# STMP3770 register map
Vendor: Freescale Semiconductor (NXP); Series: STMP37xx; File version: 1.0
CPU: other r0p0, little endian, no MPU, no FPU, 2 interrupt priority bits
Registers are 32-bit, read-write, reset 0x0 unless marked. A register's access mark holds for its fields unless they carry their own. Offsets are from the block's base; [hi:lo] are bit positions; {n}, {i} and the like mark numbered series.

## DRAM — DRAM 控制器(mDDR/SDRAM 时序、刷新与校准配置寄存器)
Base 0x800E0000
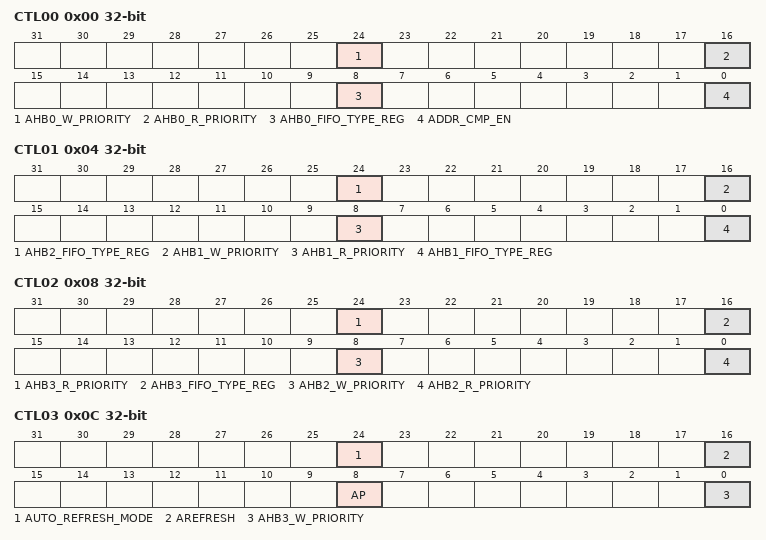
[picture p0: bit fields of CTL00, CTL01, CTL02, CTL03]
0x00 CTL00 — DRAM Control Register 00
  [24] AHB0_W_PRIORITY — Ahb0 W Priority，1位读写字段。
  [16] AHB0_R_PRIORITY — Ahb0 R Priority，1位读写字段。
  [8] AHB0_FIFO_TYPE_REG — Ahb0 Fifo Type Reg，1位读写字段。
  [0] ADDR_CMP_EN — Addr Cmp En，1位读写字段。
0x04 CTL01 — DRAM Control Register 01
  [24] AHB2_FIFO_TYPE_REG — Ahb2 Fifo Type Reg，1位读写字段。
  [16] AHB1_W_PRIORITY — Ahb1 W Priority，1位读写字段。
  [8] AHB1_R_PRIORITY — Ahb1 R Priority，1位读写字段。
  [0] AHB1_FIFO_TYPE_REG — Ahb1 Fifo Type Reg，1位读写字段。
0x08 CTL02 — DRAM Control Register 02
  [24] AHB3_R_PRIORITY — Ahb3 R Priority，1位读写字段。
  [16] AHB3_FIFO_TYPE_REG — Ahb3 Fifo Type Reg，1位读写字段。
  [8] AHB2_W_PRIORITY — Ahb2 W Priority，1位读写字段。
  [0] AHB2_R_PRIORITY — Ahb2 R Priority，1位读写字段。
0x0C CTL03 — DRAM Control Register 03
  [24] AUTO_REFRESH_MODE — Auto Refresh Mode，1位读写字段。
  [16] AREFRESH — Arefresh，1位读写字段。
  [8] AP — Ap，1位读写字段。
  [0] AHB3_W_PRIORITY — Ahb3 W Priority，1位读写字段。
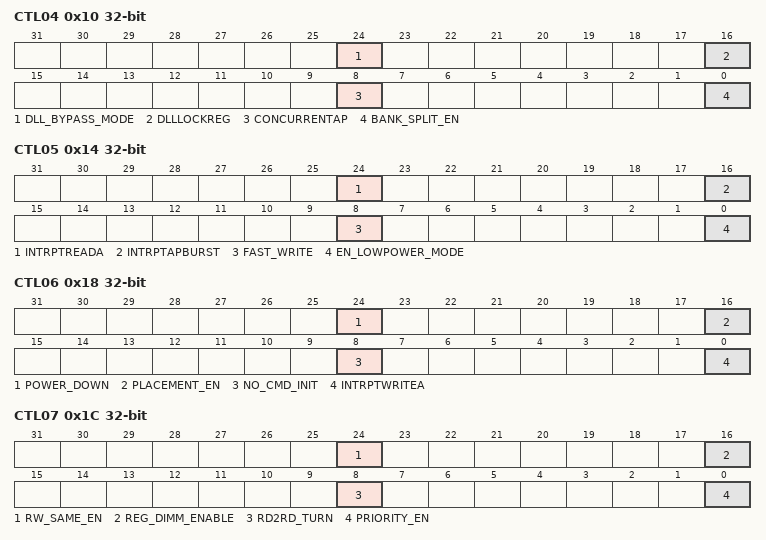
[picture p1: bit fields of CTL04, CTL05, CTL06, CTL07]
0x10 CTL04 — DRAM Control Register 04
  [24] DLL_BYPASS_MODE — Dll Bypass Mode，1位读写字段。
  [16] DLLLOCKREG — Dlllockreg，1位读写字段。
  [8] CONCURRENTAP — Concurrentap，1位读写字段。
  [0] BANK_SPLIT_EN — Bank Split En，1位读写字段。
0x14 CTL05 — DRAM Control Register 05
  [24] INTRPTREADA — Intrptreada，1位读写字段。
  [16] INTRPTAPBURST — Intrptapburst，1位读写字段。
  [8] FAST_WRITE — Fast Write，1位读写字段。
  [0] EN_LOWPOWER_MODE — En Lowpower Mode，1位读写字段。
0x18 CTL06 — DRAM Control Register 06
  [24] POWER_DOWN — Power Down，1位读写字段。
  [16] PLACEMENT_EN — Placement En，1位读写字段。
  [8] NO_CMD_INIT — No Cmd Init，1位读写字段。
  [0] INTRPTWRITEA — Intrptwritea，1位读写字段。
0x1C CTL07 — DRAM Control Register 07
  [24] RW_SAME_EN — Rw Same En，1位读写字段。
  [16] REG_DIMM_ENABLE — Reg Dimm Enable，1位读写字段。
  [8] RD2RD_TURN — Rd2Rd Turn，1位读写字段。
  [0] PRIORITY_EN — Priority En，1位读写字段。
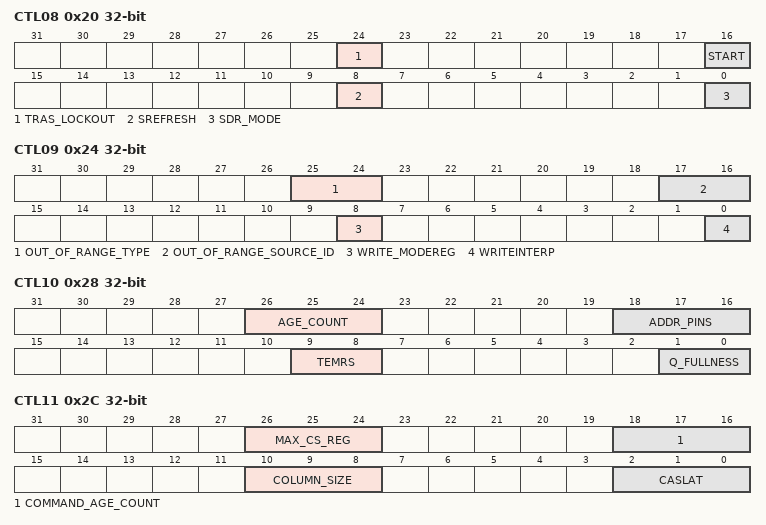
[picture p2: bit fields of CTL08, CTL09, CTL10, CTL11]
0x20 CTL08 — DRAM Control Register 08
  [24] TRAS_LOCKOUT — Tras Lockout，1位读写字段。
  [16] START — Start，1位读写字段。
  [8] SREFRESH — Srefresh，1位读写字段。
  [0] SDR_MODE — Sdr Mode，1位读写字段。
0x24 CTL09 — DRAM Control Register 09
  [25:24] OUT_OF_RANGE_TYPE — Out Of Range Type，2位读写字段。
  [17:16] OUT_OF_RANGE_SOURCE_ID — Out Of Range Source Id，2位读写字段。
  [8] WRITE_MODEREG — Write Modereg，1位读写字段。
  [0] WRITEINTERP — Writeinterp，1位读写字段。
0x28 CTL10 — DRAM Control Register 10
  [26:24] AGE_COUNT — Age Count，3位读写字段。
  [18:16] ADDR_PINS — Addr Pins，3位读写字段。
  [9:8] TEMRS — Temrs，2位读写字段。
  [1:0] Q_FULLNESS — Q Fullness，2位读写字段。
0x2C CTL11 — DRAM Control Register 11
  [26:24] MAX_CS_REG — Max Cs Reg，3位读写字段。
  [18:16] COMMAND_AGE_COUNT — Command Age Count，3位读写字段。
  [10:8] COLUMN_SIZE — Column Size，3位读写字段。
  [2:0] CASLAT — Caslat，3位读写字段。
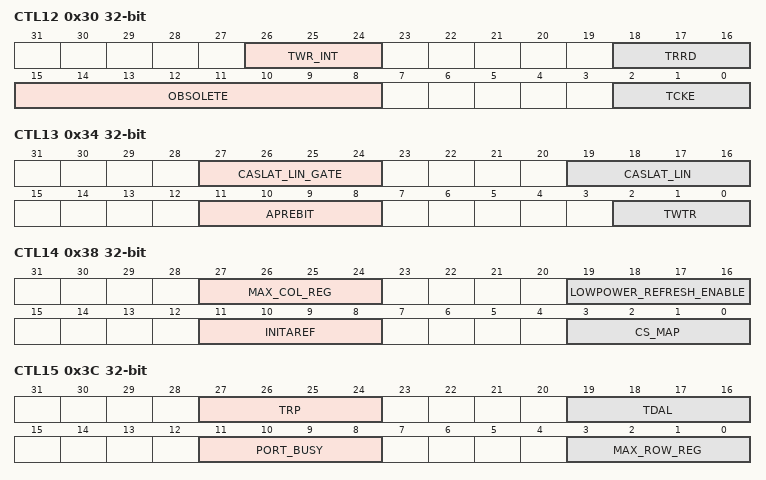
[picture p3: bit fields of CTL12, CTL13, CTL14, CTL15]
0x30 CTL12 — DRAM Control Register 12
  [26:24] TWR_INT — Twr Int，3位读写字段。
  [18:16] TRRD — Trrd，3位读写字段。
  [15:8] OBSOLETE — Obsolete，8位读写字段。
  [2:0] TCKE — Tcke，3位读写字段。
0x34 CTL13 — DRAM Control Register 13
  [27:24] CASLAT_LIN_GATE — Caslat Lin Gate，4位读写字段。
  [19:16] CASLAT_LIN — Caslat Lin，4位读写字段。
  [11:8] APREBIT — Aprebit，4位读写字段。
  [2:0] TWTR — Twtr，3位读写字段。
0x38 CTL14 — DRAM Control Register 14
  [27:24] MAX_COL_REG — Max Col Reg，4位读写字段。
  [19:16] LOWPOWER_REFRESH_ENABLE — Lowpower Refresh Enable，4位读写字段。
  [11:8] INITAREF — Initaref，4位读写字段。
  [3:0] CS_MAP — Cs Map，4位读写字段。
0x3C CTL15 — DRAM Control Register 15
  [27:24] TRP — Trp，4位读写字段。
  [19:16] TDAL — Tdal，4位读写字段。
  [11:8] PORT_BUSY — Port Busy，4位读写字段。
  [3:0] MAX_ROW_REG — Max Row Reg，4位读写字段。
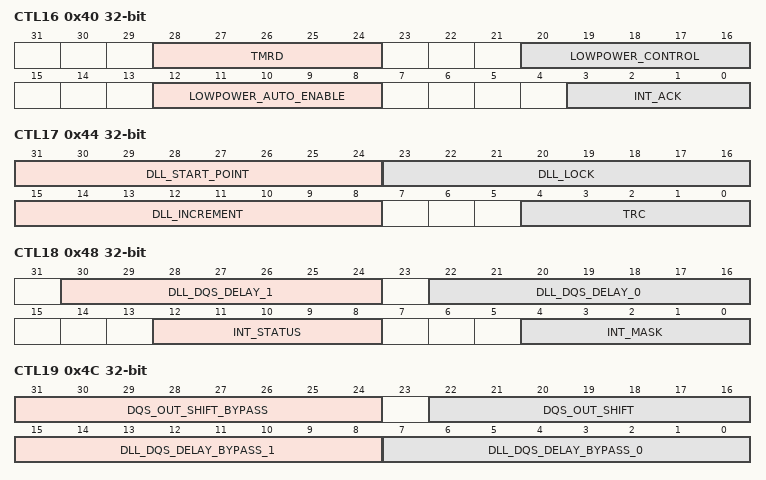
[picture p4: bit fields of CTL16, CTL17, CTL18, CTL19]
0x40 CTL16 — DRAM Control Register 16
  [28:24] TMRD — Tmrd，5位读写字段。
  [20:16] LOWPOWER_CONTROL — Lowpower Control，5位读写字段。
  [12:8] LOWPOWER_AUTO_ENABLE — Lowpower Auto Enable，5位读写字段。
  [3:0] INT_ACK — Int Ack，4位读写字段。
0x44 CTL17 — DRAM Control Register 17
  [31:24] DLL_START_POINT — Dll Start Point，8位读写字段。
  [23:16] DLL_LOCK — Dll Lock，8位读写字段。
  [15:8] DLL_INCREMENT — Dll Increment，8位读写字段。
  [4:0] TRC — Trc，5位读写字段。
0x48 CTL18 — DRAM Control Register 18
  [30:24] DLL_DQS_DELAY_1 — Dll Dqs Delay 1，7位读写字段。
  [22:16] DLL_DQS_DELAY_0 — Dll Dqs Delay 0，7位读写字段。
  [12:8] INT_STATUS — Int Status，5位读写字段。
  [4:0] INT_MASK — Int Mask，5位读写字段。
0x4C CTL19 — DRAM Control Register 19
  [31:24] DQS_OUT_SHIFT_BYPASS — Dqs Out Shift Bypass，8位读写字段。
  [22:16] DQS_OUT_SHIFT — Dqs Out Shift，7位读写字段。
  [15:8] DLL_DQS_DELAY_BYPASS_1 — Dll Dqs Delay Bypass 1，8位读写字段。
  [7:0] DLL_DQS_DELAY_BYPASS_0 — Dll Dqs Delay Bypass 0，8位读写字段。
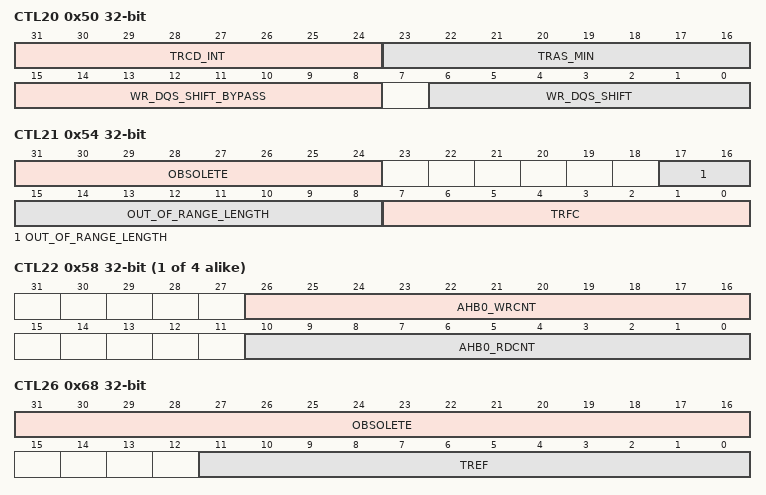
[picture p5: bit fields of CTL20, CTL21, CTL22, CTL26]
0x50 CTL20 — DRAM Control Register 20
  [31:24] TRCD_INT — Trcd Int，8位读写字段。
  [23:16] TRAS_MIN — Tras Min，8位读写字段。
  [15:8] WR_DQS_SHIFT_BYPASS — Wr Dqs Shift Bypass，8位读写字段。
  [6:0] WR_DQS_SHIFT — Wr Dqs Shift，7位读写字段。
0x54 CTL21 — DRAM Control Register 21
  [31:24] OBSOLETE — Obsolete，8位读写字段。
  [17:8] OUT_OF_RANGE_LENGTH — Out Of Range Length，10位读写字段。
  [7:0] TRFC — Trfc，8位读写字段。
{0x0+4i} CTL{i} (i=22..25) — DRAM Control Register {i}
  [26:16] AHB{i-22}_WRCNT — Ahb{i-22} Wrcnt，11位读写字段。
  [10:0] AHB{i-22}_RDCNT — Ahb{i-22} Rdcnt，11位读写字段。
0x68 CTL26 — DRAM Control Register 26
  [31:16] OBSOLETE — Obsolete，16位读写字段。
  [11:0] TREF — Tref，12位读写字段。
0x6C CTL27 — DRAM Control Register 27
  [31:0] OBSOLETE — Obsolete，32位读写字段。
0x70 CTL28 — DRAM Control Register 28
  [31:0] OBSOLETE — Obsolete，32位读写字段。
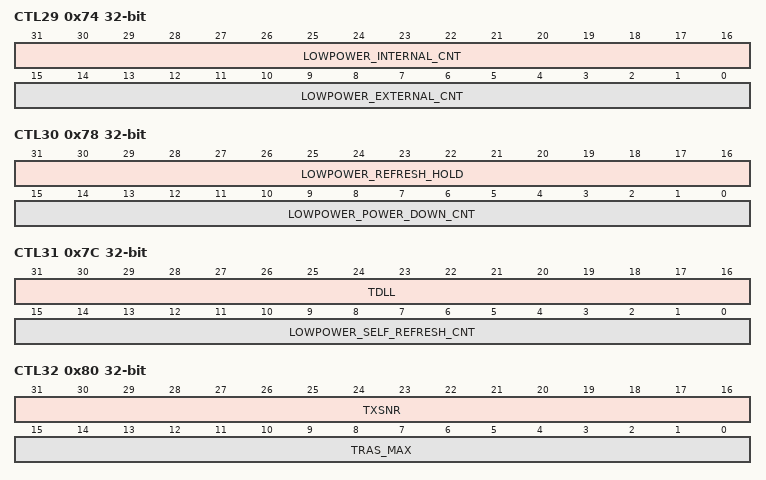
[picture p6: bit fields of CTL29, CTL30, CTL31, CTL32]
0x74 CTL29 — DRAM Control Register 29
  [31:16] LOWPOWER_INTERNAL_CNT — Lowpower Internal Cnt，16位读写字段。
  [15:0] LOWPOWER_EXTERNAL_CNT — Lowpower External Cnt，16位读写字段。
0x78 CTL30 — DRAM Control Register 30
  [31:16] LOWPOWER_REFRESH_HOLD — Lowpower Refresh Hold，16位读写字段。
  [15:0] LOWPOWER_POWER_DOWN_CNT — Lowpower Power Down Cnt，16位读写字段。
0x7C CTL31 — DRAM Control Register 31
  [31:16] TDLL — Tdll，16位读写字段。
  [15:0] LOWPOWER_SELF_REFRESH_CNT — Lowpower Self Refresh Cnt，16位读写字段。
0x80 CTL32 — DRAM Control Register 32
  [31:16] TXSNR — Txsnr，16位读写字段。
  [15:0] TRAS_MAX — Tras Max，16位读写字段。
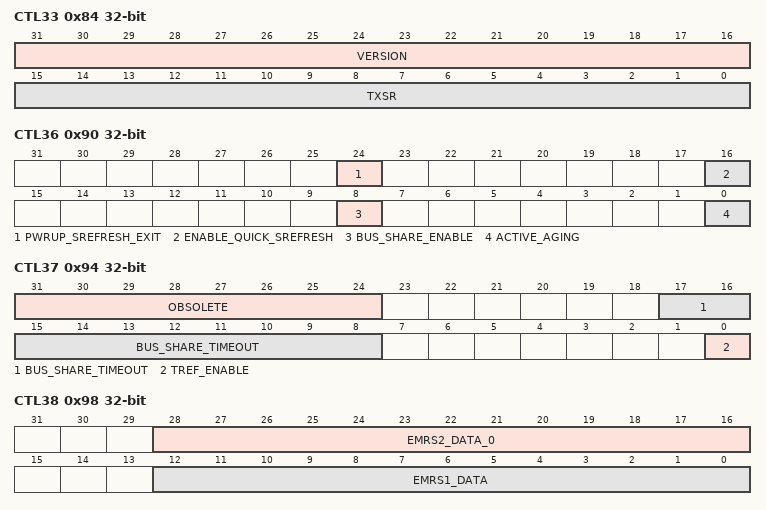
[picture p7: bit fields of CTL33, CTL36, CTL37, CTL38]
0x84 CTL33 — DRAM Control Register 33
  [31:16] VERSION — Version，16位读写字段。
  [15:0] TXSR — Txsr，16位读写字段。
0x88 CTL34 — DRAM Control Register 34
  [23:0] TINIT — Tinit，24位读写字段。
0x8C CTL35 — DRAM Control Register 35
  [30:0] OUT_OF_RANGE_ADDR — Out Of Range Addr，31位读写字段。
0x90 CTL36 — DRAM Control Register 36
  [24] PWRUP_SREFRESH_EXIT — Pwrup Srefresh Exit，1位读写字段。
  [16] ENABLE_QUICK_SREFRESH — Enable Quick Srefresh，1位读写字段。
  [8] BUS_SHARE_ENABLE — Bus Share Enable，1位读写字段。
  [0] ACTIVE_AGING — Active Aging，1位读写字段。
0x94 CTL37 — DRAM Control Register 37
  [31:24] OBSOLETE — Obsolete，8位读写字段。
  [17:8] BUS_SHARE_TIMEOUT — Bus Share Timeout，10位读写字段。
  [0] TREF_ENABLE — Tref Enable，1位读写字段。
0x98 CTL38 — DRAM Control Register 38
  [28:16] EMRS2_DATA_0 — Emrs2 Data 0，13位读写字段。
  [12:0] EMRS1_DATA — Emrs1 Data，13位读写字段。
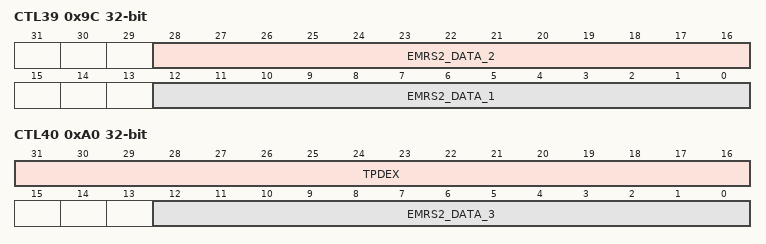
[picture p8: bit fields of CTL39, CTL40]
0x9C CTL39 — DRAM Control Register 39
  [28:16] EMRS2_DATA_2 — Emrs2 Data 2，13位读写字段。
  [12:0] EMRS2_DATA_1 — Emrs2 Data 1，13位读写字段。
0xA0 CTL40 — DRAM Control Register 40
  [31:16] TPDEX — Tpdex，16位读写字段。
  [12:0] EMRS2_DATA_3 — Emrs2 Data 3，13位读写字段。
